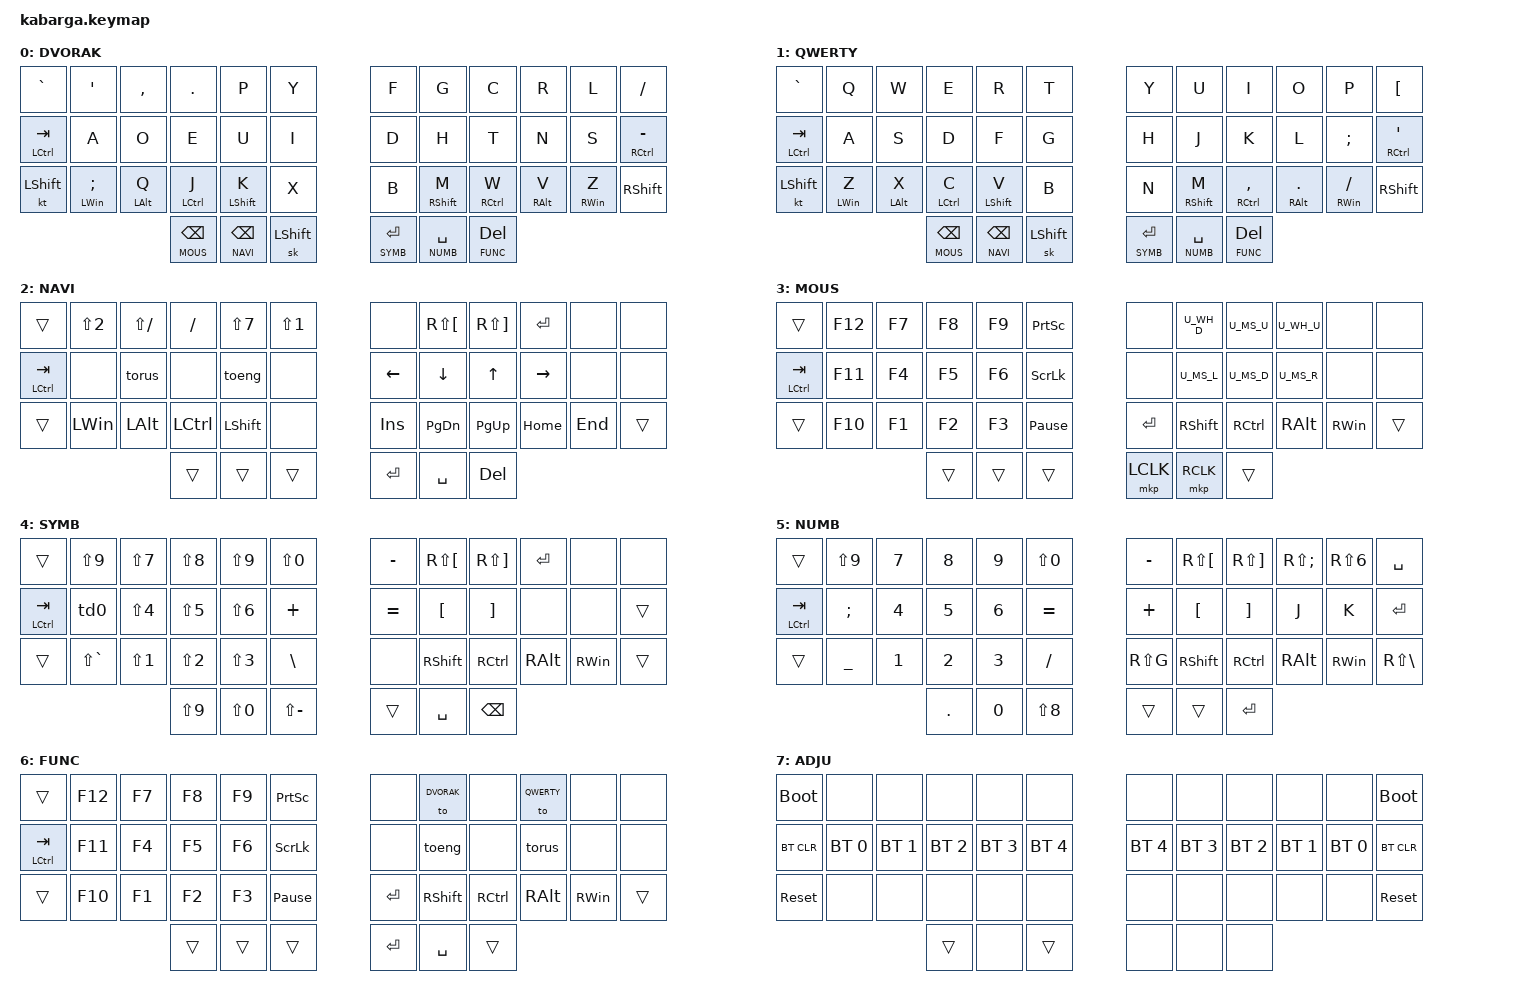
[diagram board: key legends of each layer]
#include <dt-bindings/zmk/bt.h>
#include <dt-bindings/zmk/keys.h>
#include <behaviors.dtsi>
#include "keypos_42keys_kabarga.h"
#include "mouse.dtsi"

#define DVORAK 0
#define QWERTY 1
#define NAVI 2
#define MOUS 3
#define SYMB 4
#define NUMB 5
#define FUNC 6
#define ADJU 7

#define XXX &none
#define ___ &trans

#define QUICK_TAP_MS 175

&sk {  // sticky-key config
    release-after-ms = <900>;  // release after 0.6s
    quick-release;             // no double capitalization when rolling keys
};

&sl {  // sticky-layer config
    ignore-modifiers;          // allow chording sticky mods & layers
};

&lt {  // layer-tap config
    flavor = "balanced";
    tapping-term-ms = <250>;
    quick-tap-ms = <QUICK_TAP_MS>;
};

/* Homerow mods */

#define KEYS_L LT0 LT1 LT2 LT3 LT4 LT5 LM0 LM1 LM2 LM3 LM4 LM5 LB0 LB1 LB2 LB3 LB4 LB5 // left hand
#define KEYS_R RT0 RT1 RT2 RT3 RT4 RT5 RM0 RM1 RM2 RM3 RM4 RM5 RB0 RB1 RB2 RB3 RB4 RB5 // right hand
#define THUMBS LH2 LH1 LH0 RH0 RH1 RH2                                                 // thumbs

/ {
    macros {
        assign: assign {
            label = "assign";
            compatible = "zmk,behavior-macro";
            #binding-cells = <0>;
            bindings = <&macro_tap>, <&kp COLON &kp EQUAL &kp SPACE>;
        };
        torus: torus {
            label = "torus";
            compatible = "zmk,behavior-macro";
            #binding-cells = <0>;
            bindings = <&macro_tap>, <&to QWERTY>, <&kp LA(LSHFT)>;
        };
        toeng: toeng {
            label = "toeng";
            compatible = "zmk,behavior-macro";
            #binding-cells = <0>;
            bindings = <&macro_tap>, <&to DVORAK>, <&kp LA(LSHFT)>;
        };
    };

    combos {
        compatible = "zmk,combos";
        combo_qmark {
            timeout-ms = <40>;
            layers = <QWERTY>;
            key-positions = <LM2 LM3>;
            require-prior-idle-ms = <150>;
            bindings = <&kp AMPS>; /* qmark in russian map */
        };
        combo_excl {
            timeout-ms = <40>;
            layers = <QWERTY>;
            key-positions = <LM2 LM1>;
            require-prior-idle-ms = <150>;
            bindings = <&kp EXCL>;
        };
        combo_commaRus {
            timeout-ms = <40>;
            layers = <QWERTY>;
            key-positions = <RM1 RM2>;
            require-prior-idle-ms = <150>;
            bindings = <&kp QMARK>; /* comma in russian map */
        };
        combo_dotRus {
            timeout-ms = <40>;
            layers = <QWERTY>;
            key-positions = <RM2 RM3>;
            require-prior-idle-ms = <150>;
            bindings = <&kp FSLH>; /* dot in russian map */
        };

        combo_esc {
            timeout-ms = <40>;
            key-positions = <LT3 LT2>;
            require-prior-idle-ms = <150>;
            bindings = <&kp ESC>;
        };
        combo_enter {
            timeout-ms = <40>;
            key-positions = <LT2 LT1>;
            require-prior-idle-ms = <150>;
            bindings = <&kp ENTER>;
        };
        combo_tab {
            timeout-ms = <40>;
            key-positions = <LM2 LM3>;
            require-prior-idle-ms = <150>;
            bindings = <&kp TAB>;
        };
        combo_assign {
            timeout-ms = <40>;
            key-positions = <LM3 LM4>;
            require-prior-idle-ms = <150>;
            bindings = <&assign>;
        };
        combo_del {
            timeout-ms = <40>;
            key-positions = <RT2 RT3>;
            require-prior-idle-ms = <150>;
            bindings = <&kp DEL>;
        };
        combo_bspc {
            timeout-ms = <40>;
            key-positions = <RT1 RT2>;
            require-prior-idle-ms = <150>;
            bindings = <&kp BSPC>;
        };

        combo_lpar {
            timeout-ms = <40>;
            key-positions = <RM1 RM2>;
            require-prior-idle-ms = <150>;
            bindings = <&kp LPAR>;
        };
        combo_rpar {
            timeout-ms = <40>;
            key-positions = <RM2 RM3>;
            require-prior-idle-ms = <150>;
            bindings = <&kp RPAR>;
        };

        combo_pipe {
            timeout-ms = <40>;
            key-positions = <RM2 RB1>;
            require-prior-idle-ms = <150>;
            bindings = <&kp PIPE>;
        };
    };

    behaviors {
        td0: tap_dance_0 {
            label = "td0";
            compatible = "zmk,behavior-tap-dance";
            #binding-cells = <0>;
            tapping-term-ms = <250>;
            bindings = <&kp COLON>, <&assign>;
        };
        bhl: balanced_homerow_left {
            label = "bhl";
            compatible = "zmk,behavior-hold-tap";
            #binding-cells = <2>;
        flavor = "balanced";
        tapping-term-ms = <280>;
        quick-tap-ms = <QUICK_TAP_MS>;
        require-prior-idle-ms = <150>;
        bindings = <&kp>, <&kp>;
        hold-trigger-key-positions = <6 7 8 9 10 11 18 19 20 21 22 23 30 31 32 33 34 35 39 40 41>;
        hold-trigger-on-release;
/*            tapping-term-ms = <300>;
            quick-tap-ms = <175>;
            require-prior-idle-ms = <150>;
            flavor = "balanced";
            bindings = <&kp>, <&kp>;
            hold-trigger-key-positions = <7 8 9 10 11 12 13 20 21 22 23 24 25 32 33 34 35 36 37 42 43 44 45>;
            hold-trigger-on-release; */
        };
        bhr: balanced_homerow_right {
            label = "bhr";
            compatible = "zmk,behavior-hold-tap";
            #binding-cells = <2>;
        flavor = "balanced";
        tapping-term-ms = <280>;
        quick-tap-ms = <QUICK_TAP_MS>;
        require-prior-idle-ms = <150>;
        bindings = <&kp>, <&kp>;
        hold-trigger-key-positions = <0 1 2 3 4 5 12 13 14 15 16 17 24 25 26 27 28 29 36 37 38>;
        hold-trigger-on-release;
/*            tapping-term-ms = <300>;
            quick-tap-ms = <175>;
            require-prior-idle-ms = <150>;
            flavor = "balanced";
            bindings = <&kp>, <&kp>;
            hold-trigger-key-positions = <0 1 2 3 4 5 6 14 15 16 17 18 19 26 27 28 29 30 31 38 39 40 41>;
            hold-trigger-on-release; */
        };
        mo_tog: behavior_mo_tog {
            label = "mo_tog";
            compatible = "zmk,behavior-hold-tap";
            #binding-cells = <2>;
            flavor = "hold-preferred";
            tapping-term-ms = <200>;
            bindings = <&mo>, <&tog>;
        };
    };

    conditional_layers {
        compatible = "zmk,conditional-layers";
        tri_layer {
            if-layers = <NAVI FUNC>;
            then-layer = <ADJU>;
        };
    };

    keymap {
        compatible = "zmk,keymap";

        DVORAK {
            bindings = <
         &kp GRAVE      &kp SQT         &kp COMMA    &kp DOT        &kp P          &kp Y          &kp F      &kp G            &kp C            &kp R         &kp L        &kp SLASH
         &mt LCTRL TAB  &kp A           &kp O        &kp E          &kp U          &kp I          &kp D      &kp H            &kp T            &kp N         &kp S        &mt RCTRL MINUS
         &kt LSHFT      &bhl LWIN SEMI  &bhl LALT Q  &bhl LCTRL J   &bhl LSHFT K   &kp X          &kp B      &bhr RSHFT M     &bhr RCTRL W     &bhr RALT V   &bhr RWIN Z  &kp RSHFT
                                                     &lt MOUS BSPC  &lt NAVI BSPC  &sk LSHFT      &lt SYMB ENTER   &lt NUMB SPACE   &lt FUNC DEL
            >;
        };

        QWERTY {
            bindings = <
         &kp GRAVE      &kp Q        &kp W        &kp E          &kp R          &kp T          &kp Y      &kp U           &kp I             &kp O          &kp P           &kp LBKT
         &mt LCTRL TAB  &kp A        &kp S        &kp D          &kp F          &kp G          &kp H      &kp J           &kp K             &kp L          &kp SEMI        &mt RCTRL SQT
         &kt LSHFT      &bhl LWIN Z  &bhl LALT X  &bhl LCTRL C   &bhl LSHFT V   &kp B          &kp N      &bhr RSHFT M    &bhr RCTRL COMMA  &bhr RALT DOT  &bhr RWIN FSLH  &kp RSHFT
                                                  &lt MOUS BSPC  &lt NAVI BSPC  &sk LSHFT      &lt SYMB ENTER  &lt NUMB SPACE    &lt FUNC DEL
            >;
        };

        NAVI {
// for russian layout
// S(KC_4) -> ;    S(KC_2) -> "    KC_SLSH -> .   S(KC_SLSH) -> ,  S(KC_7) -> ?    S(KC_1) -> !   S(KC_6) -> :
            bindings = <
        &trans         &kp LS(N2)  &kp LS(SLASH)  &kp SLASH  &kp LS(N7)  &kp LS(N1)         &none     &kp RS(LBKT)  &kp RS(RBKT)  &kp ENTER  &none    &none
        &mt LCTRL TAB  &none       &torus         &none      &toeng      &none              &kp LEFT  &kp DOWN      &kp UP        &kp RIGHT  &none    &none
        &trans         &kp LWIN    &kp LALT       &kp LCTRL  &kp LSHFT   &none              &kp INS   &kp PG_DN     &kp PG_UP     &kp HOME   &kp END  &trans
                                                  &trans     &trans      &trans             &kp ENTER     &kp SPACE     &kp DEL
            >;
        };

        MOUS {
            bindings = <
        &trans         &kp F12   &kp F7   &kp F8  &kp F9  &kp PSCRN        &none      U_WH_D      U_MS_U     U_WH_U      &none     &none 
        &mt LCTRL TAB  &kp F11   &kp F4   &kp F5  &kp F6  &kp SLCK         &none      U_MS_L      U_MS_D     U_MS_R      &none     &none
        &trans         &kp F10   &kp F1   &kp F2  &kp F3  &kp PAUSE_BREAK  &kp ENTER  &kp RSHFT   &kp RCTRL  &kp RALT    &kp RWIN  &trans
                                          &trans  &trans  &trans           &mkp LCLK   &mkp RCLK  &trans
            >;
        };

        SYMB {
            bindings = <
        &trans         &kp LS(N9)     &kp LS(N7)  &kp LS(N8)  &kp LS(N9)     &kp LS(N0)               &kp MINUS  &kp RS(LBKT)  &kp RS(RBKT)  &kp ENTER  &none      &none
        &mt LCTRL TAB  &td0           &kp LS(N4)  &kp LS(N5)  &kp LS(N6)     &kp PLUS                 &kp EQUAL  &kp LBKT      &kp RBKT   &none       &none  &trans /* &td0 */
        &trans         &kp LS(GRAVE)  &kp LS(N1)  &kp LS(N2)  &kp LS(N3)     &kp BACKSLASH            &none      &kp RSHFT     &kp RCTRL  &kp RALT    &kp RWIN   &trans
                                      &kp LS(N9)  &kp LS(N0)  &kp LS(MINUS)                           &trans        &kp SPACE  &kp BSPC
            >;
        };

        NUMB {
            bindings = <
        &trans         &kp LS(N9)     &kp N7      &kp N8     &kp N9         &kp LS(N0)             &kp MINUS  &kp RS(LBKT)  &kp RS(RBKT)  &kp RS(SEMI)  &kp RS(N6)   &kp SPACE
        &mt LCTRL TAB  &kp SEMI       &kp N4      &kp N5     &kp N6         &kp EQUAL              &kp PLUS   &kp LBKT      &kp RBKT      &kp J         &kp K        &kp ENTER
        &trans         &kp UNDER      &kp N1      &kp N2     &kp N3         &kp SLASH              &kp RS(G)  &kp RSHFT     &kp RCTRL     &kp RALT      &kp RWIN     &kp RS(BACKSLASH)
                                      &kp DOT     &kp N0     &kp LS(N8)                            &trans        &trans        &kp ENTER
            >;
        };

        FUNC {
            bindings = <
        &trans         &kp F12   &kp F7   &kp F8  &kp F9  &kp PSCRN        &none      &to DVORAK  &none      &to QWERTY  &none     &none
        &mt LCTRL TAB  &kp F11   &kp F4   &kp F5  &kp F6  &kp SLCK         &none      &toeng      &none      &torus      &none     &none
        &trans         &kp F10   &kp F1   &kp F2  &kp F3  &kp PAUSE_BREAK  &kp ENTER  &kp RSHFT   &kp RCTRL  &kp RALT    &kp RWIN  &trans
                                 &trans  &trans  &trans                    &kp ENTER   &kp SPACE  &trans
            >;
        };

        ADJU {
            bindings = <
       &bootloader    &none         &none         &none         &none         &none           &none         &none         &none         &none         &none          &bootloader
       &bt BT_CLR     &bt BT_SEL 0  &bt BT_SEL 1  &bt BT_SEL 2  &bt BT_SEL 3  &bt BT_SEL 4    &bt BT_SEL 4  &bt BT_SEL 3  &bt BT_SEL 2  &bt BT_SEL 1  &bt BT_SEL 0   &bt BT_CLR
       &sys_reset     &none         &none         &none         &none         &none           &none         &none         &none         &none         &none          &sys_reset
                                    &trans        &none         &trans                        &none         &none         &none
            >;
        };

    };
};
